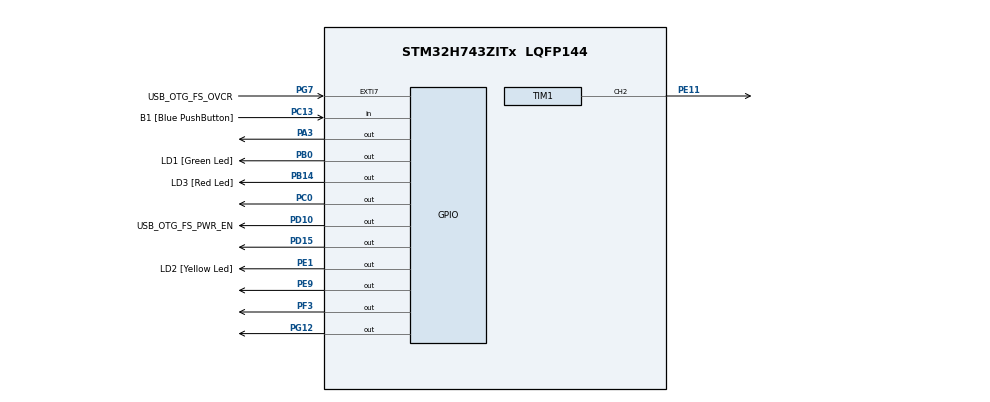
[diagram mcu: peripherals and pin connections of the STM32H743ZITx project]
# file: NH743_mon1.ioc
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Mcu.Family=STM32H7
Mcu.Name=STM32H743ZITx
Mcu.Package=LQFP144
NVIC.PriorityGroup=NVIC_PRIORITYGROUP_4
PA1.Signal=ETH_REF_CLK
PA11.Signal=USB_OTG_FS_DM
PA12.Signal=USB_OTG_FS_DP
PA13\ (JTMS/SWDIO).GPIO_Label=JTMS
PA13\ (JTMS/SWDIO).Signal=DEBUG_JTMS-SWDIO
PA14\ (JTCK/SWCLK).GPIO_Label=JTCK
PA14\ (JTCK/SWCLK).Signal=DEBUG_JTCK-SWCLK
PA2.Signal=ETH_MDIO
PA3.GPIO_Speed=GPIO_SPEED_FREQ_HIGH
PA3.PinState=GPIO_PIN_SET
PA3.Signal=GPIO_Output
PA7.Signal=ETH_CRS_DV
PA8.Signal=USB_OTG_FS_SOF
PA9.Signal=USB_OTG_FS_VBUS
PB0.GPIO_Label=LD1 [Green Led]
PB0.Signal=GPIO_Output
PB13.Signal=ETH_TXD1
PB14.GPIO_Label=LD3 [Red Led]
PB14.Signal=GPIO_Output
PC0.GPIO_Speed=GPIO_SPEED_FREQ_HIGH
PC0.PinState=GPIO_PIN_SET
PC0.Signal=GPIO_Output
PC1.Signal=ETH_MDC
PC13.GPIO_Label=B1 [Blue PushButton]
PC13.Signal=GPIO_Input
PC14-OSC32_IN\ (OSC32_IN).Signal=RCC_OSC32_IN
PC15-OSC32_OUT\ (OSC32_OUT).Signal=RCC_OSC32_OUT
PC4.Signal=ETH_RXD0
PC5.Signal=ETH_RXD1
PD10.GPIO_Label=USB_OTG_FS_PWR_EN
PD10.Signal=GPIO_Output
PD15.Signal=GPIO_Output
PD8.GPIO_Label=STLINK_RX
PD8.Signal=USART3_TX
PD9.GPIO_Label=STLINK_TX
PD9.Signal=USART3_RX
PE1.GPIO_Label=LD2 [Yellow Led]
PE1.Signal=GPIO_Output
PE11.Signal=S_TIM1_CH2
PE14.Signal=S_TIM1_CH4
PE9.Signal=GPIO_Output
PF3.GPIO_Speed=GPIO_SPEED_FREQ_HIGH
PF3.PinState=GPIO_PIN_SET
PF3.Signal=GPIO_Output
PG11.Signal=ETH_TX_EN
PG12.GPIO_Speed=GPIO_SPEED_FREQ_HIGH
PG12.PinState=GPIO_PIN_SET
PG12.Signal=GPIO_Output
PG13.Signal=ETH_TXD0
PG7.GPIO_Label=USB_OTG_FS_OVCR
PG7.Signal=GPXTI7
PH0-OSC_IN\ (PH0).Signal=RCC_OSC_IN
PH1-OSC_OUT\ (PH1).Signal=RCC_OSC_OUT
ProjectManager.HeapSize=0x200
ProjectManager.StackSize=0x400
ProjectManager.TargetToolchain=STM32CubeIDE
RCC.ADCFreq_Value=129000000
RCC.APB1Freq_Value=16000000
RCC.APB2Freq_Value=16000000
RCC.APB3Freq_Value=16000000
RCC.APB4Freq_Value=16000000
RCC.CortexFreq_Value=64000000
RCC.HCLKFreq_Value=16000000
RCC.HPRE=RCC_HCLK_DIV4
RCC.SYSCLKFreq_VALUE=64000000
RCC.USBFreq_Value=129000000
SH.S_TIM1_CH2.0=TIM1_CH2,PWM Generation2 CH2
SH.S_TIM1_CH4.0=TIM1_CH4
TIM1.AutoReloadPreload=TIM_AUTORELOAD_PRELOAD_ENABLE
TIM1.AutomaticOutput=TIM_AUTOMATICOUTPUT_DISABLE
TIM1.Break2Polarity=TIM_BREAK2POLARITY_LOW
TIM1.BreakPolarity=TIM_BREAKPOLARITY_HIGH
TIM1.Channel-PWM\ Generation2\ CH2=TIM_CHANNEL_2
TIM1.OC2Preload_PWM=DISABLE
TIM1.OCIdleState_2=TIM_OCIDLESTATE_SET
TIM1.OCMode_PWM-PWM\ Generation2\ CH2=TIM_OCMODE_PWM2
TIM1.OCPolarity_2=TIM_OCPOLARITY_LOW
TIM1.Period=30000
TIM1.Pulse-PWM\ Generation2\ CH2=7000
TIM1.RepetitionCounter=0
TIM1.TIM_MasterOutputTrigger=TIM_TRGO_ENABLE
TIM1.TIM_MasterOutputTrigger2=TIM_TRGO2_ENABLE
board=NUCLEO-H743ZI2

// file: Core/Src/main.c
/* USER CODE BEGIN Header */
/**
  ******************************************************************************
  * @file           : main.c
  * @brief          : Main program body
  ******************************************************************************
  * @attention
  *
  * Copyright (c) 2024 STMicroelectronics.
  * All rights reserved.
  *
  * This software is licensed under terms that can be found in the LICENSE file
  * in the root directory of this software component.
  * If no LICENSE file comes with this software, it is provided AS-IS.
  *
  ******************************************************************************
  Программа управления электродвигателем (мотором) постоянного тока.
  Используемое оборудование:
  1. NUCLEO-H743ZI2 (верс. NUH743ZI$AT1, MB1364C, MB1364-H743ZI-C01 F192404187)
  с  микроконтроллером STM743ZIT6U;
  2. MonsterMoto-Shield на базе VNH2SP3;
  3. Электродвигатель (мотор) постоянного тока;

  Среда разработки STM32CubeIDE v. 1.14.0
  Татаринцев Н.И, 01.05.2024 г.

  ******************************************************************************
  */
/* USER CODE END Header */
#include "main.h"

TIM_HandleTypeDef htim1;

void SystemClock_Config(void);
static void MX_GPIO_Init(void);
static void MX_TIM1_Init(void);

int main(void)
{

  /* MCU Configuration--------------------------------------------------------*/

  /* Reset of all peripherals, Initializes the Flash interface and the Systick. */
  HAL_Init();

  /* Configure the system clock */
  SystemClock_Config();

  /* Initialize all configured peripherals */
  MX_GPIO_Init();
  MX_TIM1_Init();

  /* USER CODE BEGIN 2 */

  /* ЗАПУСК ШИМ */

  /* Запуск ШИМ моста/мотора M1.
     Таймер 1, канал 2, Коннектор/Пин CN10/6, Порт PE11 (TIM1_CH2); */
     HAL_TIM_PWM_Start_IT(&htim1, TIM_CHANNEL_2);

     /* USER CODE END 2 */

  /* Infinite loop */
  /* USER CODE BEGIN WHILE */
  while (1)
  {

  /* ВРАЩЕНИЕ ЭЛЕКТРОДВИГАТЕЛЯ (МОТОРА) M1 ПРОТИВ ЧАСОВОЙ СТРЕЛКИ (CCW): */

	  /* Установка разрешения (EN1) на работу моста/мотора М1.
	     Коннектор/Пин CN9/1, Порт PA3; */
	  	 HAL_GPIO_WritePin(GPIOA, GPIO_PIN_3, GPIO_PIN_SET);

	  /* Разрешение на вращение мотора М1 против часовой стрелки (CCW).
	     Вход В драйвера 1 (INB1), Коннектор/Пин CN7/20, Порт PF3; */
	     HAL_GPIO_WritePin(GPIOF, GPIO_PIN_3, GPIO_PIN_SET);

	  /* Запрет на вращение мотора М1 по часовой стрелке (CW).
	     Вход В драйвера 1 (INA1),Коннектор/Пин CN10/2, Порт PG12; */
	  	 HAL_GPIO_WritePin(GPIOG, GPIO_PIN_12, GPIO_PIN_RESET);

	  /* Задержка времени на вращение мотора М1 против часовой стрелки */
	  	 HAL_Delay(5000);
      /* Снятие разрешения (EN1) на работу моста/мотора М1.
         Коннектор/Пин CN9/1, Порт PA3; */
	  	 HAL_GPIO_WritePin(GPIOA, GPIO_PIN_3, GPIO_PIN_RESET);
	     HAL_Delay(1000);

  /* ВРАЩЕНИЕ ЭЛЕКТРОДВИГАТЕЛЯ (МОТОРА) M1 ПО ЧАСОВОЙ СТРЕЛКЕ (CW):

       /* Установка разрешения (EN1) на работу моста/мотора М1.
          Коннектор/Пин CN9/1, Порт PA3; */
	  	  HAL_GPIO_WritePin(GPIOA, GPIO_PIN_3, GPIO_PIN_SET);

	   /* Разрешение на вращение мотора М1 по часовой стрелке (CW).
	      Вход В драйвера 1 (INA1), Коннектор/Пин CN10/2, Порт PG12; */
	  	  HAL_GPIO_WritePin(GPIOG, GPIO_PIN_12, GPIO_PIN_SET);

	   /* Запрет на вращение мотора М1 против часовой стрелки (CCW).
	  	  Вход В драйвера 1 (INB1), Коннектор/Пин CN7/20, Порт PF3; */
	   	  HAL_GPIO_WritePin(GPIOF, GPIO_PIN_3, GPIO_PIN_RESET);

	   	/* Задержка времени на вращение мотора М1 по часовой стрелке */
	   	   HAL_Delay(5000);

	   	/* Снятие разрешения (EN1) на работу моста/мотора М1.
	   	   Коннектор/Пин CN9/1, Порт PA3; */
	       HAL_GPIO_WritePin(GPIOA, GPIO_PIN_3, GPIO_PIN_RESET);
	       HAL_Delay(1000);

    /* USER CODE END WHILE */

  }
}

void SystemClock_Config(void)
{
  RCC_OscInitTypeDef RCC_OscInitStruct = {0};
  RCC_ClkInitTypeDef RCC_ClkInitStruct = {0};

  /** Supply configuration update enable
  */
  HAL_PWREx_ConfigSupply(PWR_LDO_SUPPLY);

  /** Configure the main internal regulator output voltage
  */
  __HAL_PWR_VOLTAGESCALING_CONFIG(PWR_REGULATOR_VOLTAGE_SCALE3);

  while(!__HAL_PWR_GET_FLAG(PWR_FLAG_VOSRDY)) {}

  /** Initializes the RCC Oscillators according to the specified parameters
  * in the RCC_OscInitTypeDef structure.
  */
  RCC_OscInitStruct.OscillatorType = RCC_OSCILLATORTYPE_HSI;
  RCC_OscInitStruct.HSIState = RCC_HSI_DIV1;
  RCC_OscInitStruct.HSICalibrationValue = RCC_HSICALIBRATION_DEFAULT;
  RCC_OscInitStruct.PLL.PLLState = RCC_PLL_NONE;
  if (HAL_RCC_OscConfig(&RCC_OscInitStruct) != HAL_OK)
  {
    Error_Handler();
  }

  /** Initializes the CPU, AHB and APB buses clocks
  */
  RCC_ClkInitStruct.ClockType = RCC_CLOCKTYPE_HCLK|RCC_CLOCKTYPE_SYSCLK
                              |RCC_CLOCKTYPE_PCLK1|RCC_CLOCKTYPE_PCLK2
                              |RCC_CLOCKTYPE_D3PCLK1|RCC_CLOCKTYPE_D1PCLK1;
  RCC_ClkInitStruct.SYSCLKSource = RCC_SYSCLKSOURCE_HSI;
  RCC_ClkInitStruct.SYSCLKDivider = RCC_SYSCLK_DIV1;
  RCC_ClkInitStruct.AHBCLKDivider = RCC_HCLK_DIV4;
  RCC_ClkInitStruct.APB3CLKDivider = RCC_APB3_DIV1;
  RCC_ClkInitStruct.APB1CLKDivider = RCC_APB1_DIV1;
  RCC_ClkInitStruct.APB2CLKDivider = RCC_APB2_DIV1;
  RCC_ClkInitStruct.APB4CLKDivider = RCC_APB4_DIV1;

  if (HAL_RCC_ClockConfig(&RCC_ClkInitStruct, FLASH_LATENCY_0) != HAL_OK)
  {
    Error_Handler();
  }
}

static void MX_TIM1_Init(void)
{

  TIM_MasterConfigTypeDef sMasterConfig = {0};
  TIM_OC_InitTypeDef sConfigOC = {0};
  TIM_BreakDeadTimeConfigTypeDef sBreakDeadTimeConfig = {0};

  htim1.Instance = TIM1;
  htim1.Init.Prescaler = 0;
  htim1.Init.CounterMode = TIM_COUNTERMODE_UP;
  htim1.Init.Period = 30000;
  htim1.Init.ClockDivision = TIM_CLOCKDIVISION_DIV1;
  htim1.Init.RepetitionCounter = 0;
  htim1.Init.AutoReloadPreload = TIM_AUTORELOAD_PRELOAD_ENABLE;
  if (HAL_TIM_PWM_Init(&htim1) != HAL_OK)
  {
    Error_Handler();
  }
  sMasterConfig.MasterOutputTrigger = TIM_TRGO_ENABLE;
  sMasterConfig.MasterOutputTrigger2 = TIM_TRGO2_ENABLE;
  sMasterConfig.MasterSlaveMode = TIM_MASTERSLAVEMODE_DISABLE;
  if (HAL_TIMEx_MasterConfigSynchronization(&htim1, &sMasterConfig) != HAL_OK)
  {
    Error_Handler();
  }
  sConfigOC.OCMode = TIM_OCMODE_PWM2;
  sConfigOC.Pulse = 7000;
  sConfigOC.OCPolarity = TIM_OCPOLARITY_LOW;
  sConfigOC.OCNPolarity = TIM_OCNPOLARITY_HIGH;
  sConfigOC.OCFastMode = TIM_OCFAST_DISABLE;
  sConfigOC.OCIdleState = TIM_OCIDLESTATE_SET;
  sConfigOC.OCNIdleState = TIM_OCNIDLESTATE_RESET;
  if (HAL_TIM_PWM_ConfigChannel(&htim1, &sConfigOC, TIM_CHANNEL_2) != HAL_OK)
  {
    Error_Handler();
  }
  __HAL_TIM_DISABLE_OCxPRELOAD(&htim1, TIM_CHANNEL_2);
  sBreakDeadTimeConfig.OffStateRunMode = TIM_OSSR_DISABLE;
  sBreakDeadTimeConfig.OffStateIDLEMode = TIM_OSSI_DISABLE;
  sBreakDeadTimeConfig.LockLevel = TIM_LOCKLEVEL_OFF;
  sBreakDeadTimeConfig.DeadTime = 0;
  sBreakDeadTimeConfig.BreakState = TIM_BREAK_DISABLE;
  sBreakDeadTimeConfig.BreakPolarity = TIM_BREAKPOLARITY_HIGH;
  sBreakDeadTimeConfig.BreakFilter = 0;
  sBreakDeadTimeConfig.Break2State = TIM_BREAK2_DISABLE;
  sBreakDeadTimeConfig.Break2Polarity = TIM_BREAK2POLARITY_LOW;
  sBreakDeadTimeConfig.Break2Filter = 0;
  sBreakDeadTimeConfig.AutomaticOutput = TIM_AUTOMATICOUTPUT_DISABLE;
  if (HAL_TIMEx_ConfigBreakDeadTime(&htim1, &sBreakDeadTimeConfig) != HAL_OK)
  {
    Error_Handler();
  }
  HAL_TIM_MspPostInit(&htim1);

}

static void MX_GPIO_Init(void)
{
  GPIO_InitTypeDef GPIO_InitStruct = {0};

  /* GPIO Ports Clock Enable */
  __HAL_RCC_GPIOC_CLK_ENABLE();
  __HAL_RCC_GPIOF_CLK_ENABLE();
  __HAL_RCC_GPIOH_CLK_ENABLE();
  __HAL_RCC_GPIOA_CLK_ENABLE();
  __HAL_RCC_GPIOB_CLK_ENABLE();
  __HAL_RCC_GPIOE_CLK_ENABLE();
  __HAL_RCC_GPIOD_CLK_ENABLE();
  __HAL_RCC_GPIOG_CLK_ENABLE();

  /*Configure GPIO pin Output Level */
  HAL_GPIO_WritePin(GPIOF, GPIO_PIN_3, GPIO_PIN_SET);

  /*Configure GPIO pin Output Level */
  HAL_GPIO_WritePin(GPIOC, GPIO_PIN_0, GPIO_PIN_SET);

  /*Configure GPIO pin Output Level */
  HAL_GPIO_WritePin(GPIOA, GPIO_PIN_3, GPIO_PIN_SET);

  /*Configure GPIO pin Output Level */
  HAL_GPIO_WritePin(GPIOB, LD1_Pin|LD3_Pin, GPIO_PIN_RESET);

  /*Configure GPIO pin Output Level */
  HAL_GPIO_WritePin(GPIOE, GPIO_PIN_9|LD2_Pin, GPIO_PIN_RESET);

  /*Configure GPIO pin Output Level */
  HAL_GPIO_WritePin(GPIOD, USB_OTG_FS_PWR_EN_Pin|GPIO_PIN_15, GPIO_PIN_RESET);

  /*Configure GPIO pin Output Level */
  HAL_GPIO_WritePin(GPIOG, GPIO_PIN_12, GPIO_PIN_SET);

  /*Configure GPIO pin : B1_Pin */
  GPIO_InitStruct.Pin = B1_Pin;
  GPIO_InitStruct.Mode = GPIO_MODE_INPUT;
  GPIO_InitStruct.Pull = GPIO_NOPULL;
  HAL_GPIO_Init(B1_GPIO_Port, &GPIO_InitStruct);

  /*Configure GPIO pin : PF3 */
  GPIO_InitStruct.Pin = GPIO_PIN_3;
  GPIO_InitStruct.Mode = GPIO_MODE_OUTPUT_PP;
  GPIO_InitStruct.Pull = GPIO_NOPULL;
  GPIO_InitStruct.Speed = GPIO_SPEED_FREQ_HIGH;
  HAL_GPIO_Init(GPIOF, &GPIO_InitStruct);

  /*Configure GPIO pin : PC0 */
  GPIO_InitStruct.Pin = GPIO_PIN_0;
  GPIO_InitStruct.Mode = GPIO_MODE_OUTPUT_PP;
  GPIO_InitStruct.Pull = GPIO_NOPULL;
  GPIO_InitStruct.Speed = GPIO_SPEED_FREQ_HIGH;
  HAL_GPIO_Init(GPIOC, &GPIO_InitStruct);

  /*Configure GPIO pins : PC1 PC4 PC5 */
  GPIO_InitStruct.Pin = GPIO_PIN_1|GPIO_PIN_4|GPIO_PIN_5;
  GPIO_InitStruct.Mode = GPIO_MODE_AF_PP;
  GPIO_InitStruct.Pull = GPIO_NOPULL;
  GPIO_InitStruct.Speed = GPIO_SPEED_FREQ_LOW;
  GPIO_InitStruct.Alternate = GPIO_AF11_ETH;
  HAL_GPIO_Init(GPIOC, &GPIO_InitStruct);

  /*Configure GPIO pins : PA1 PA2 PA7 */
  GPIO_InitStruct.Pin = GPIO_PIN_1|GPIO_PIN_2|GPIO_PIN_7;
  GPIO_InitStruct.Mode = GPIO_MODE_AF_PP;
  GPIO_InitStruct.Pull = GPIO_NOPULL;
  GPIO_InitStruct.Speed = GPIO_SPEED_FREQ_LOW;
  GPIO_InitStruct.Alternate = GPIO_AF11_ETH;
  HAL_GPIO_Init(GPIOA, &GPIO_InitStruct);

  /*Configure GPIO pin : PA3 */
  GPIO_InitStruct.Pin = GPIO_PIN_3;
  GPIO_InitStruct.Mode = GPIO_MODE_OUTPUT_PP;
  GPIO_InitStruct.Pull = GPIO_NOPULL;
  GPIO_InitStruct.Speed = GPIO_SPEED_FREQ_HIGH;
  HAL_GPIO_Init(GPIOA, &GPIO_InitStruct);

  /*Configure GPIO pins : LD1_Pin LD3_Pin */
  GPIO_InitStruct.Pin = LD1_Pin|LD3_Pin;
  GPIO_InitStruct.Mode = GPIO_MODE_OUTPUT_PP;
  GPIO_InitStruct.Pull = GPIO_NOPULL;
  GPIO_InitStruct.Speed = GPIO_SPEED_FREQ_LOW;
  HAL_GPIO_Init(GPIOB, &GPIO_InitStruct);

  /*Configure GPIO pins : PE9 LD2_Pin */
  GPIO_InitStruct.Pin = GPIO_PIN_9|LD2_Pin;
  GPIO_InitStruct.Mode = GPIO_MODE_OUTPUT_PP;
  GPIO_InitStruct.Pull = GPIO_NOPULL;
  GPIO_InitStruct.Speed = GPIO_SPEED_FREQ_LOW;
  HAL_GPIO_Init(GPIOE, &GPIO_InitStruct);

  /*Configure GPIO pin : PB13 */
  GPIO_InitStruct.Pin = GPIO_PIN_13;
  GPIO_InitStruct.Mode = GPIO_MODE_AF_PP;
  GPIO_InitStruct.Pull = GPIO_NOPULL;
  GPIO_InitStruct.Speed = GPIO_SPEED_FREQ_LOW;
  GPIO_InitStruct.Alternate = GPIO_AF11_ETH;
  HAL_GPIO_Init(GPIOB, &GPIO_InitStruct);

  /*Configure GPIO pins : STLINK_RX_Pin STLINK_TX_Pin */
  GPIO_InitStruct.Pin = STLINK_RX_Pin|STLINK_TX_Pin;
  GPIO_InitStruct.Mode = GPIO_MODE_AF_PP;
  GPIO_InitStruct.Pull = GPIO_NOPULL;
  GPIO_InitStruct.Speed = GPIO_SPEED_FREQ_LOW;
  GPIO_InitStruct.Alternate = GPIO_AF7_USART3;
  HAL_GPIO_Init(GPIOD, &GPIO_InitStruct);

  /*Configure GPIO pins : USB_OTG_FS_PWR_EN_Pin PD15 */
  GPIO_InitStruct.Pin = USB_OTG_FS_PWR_EN_Pin|GPIO_PIN_15;
  GPIO_InitStruct.Mode = GPIO_MODE_OUTPUT_PP;
  GPIO_InitStruct.Pull = GPIO_NOPULL;
  GPIO_InitStruct.Speed = GPIO_SPEED_FREQ_LOW;
  HAL_GPIO_Init(GPIOD, &GPIO_InitStruct);

  /*Configure GPIO pin : USB_OTG_FS_OVCR_Pin */
  GPIO_InitStruct.Pin = USB_OTG_FS_OVCR_Pin;
  GPIO_InitStruct.Mode = GPIO_MODE_IT_RISING;
  GPIO_InitStruct.Pull = GPIO_NOPULL;
  HAL_GPIO_Init(USB_OTG_FS_OVCR_GPIO_Port, &GPIO_InitStruct);

  /*Configure GPIO pins : PA8 PA11 PA12 */
  GPIO_InitStruct.Pin = GPIO_PIN_8|GPIO_PIN_11|GPIO_PIN_12;
  GPIO_InitStruct.Mode = GPIO_MODE_AF_PP;
  GPIO_InitStruct.Pull = GPIO_NOPULL;
  GPIO_InitStruct.Speed = GPIO_SPEED_FREQ_LOW;
  GPIO_InitStruct.Alternate = GPIO_AF10_OTG1_FS;
  HAL_GPIO_Init(GPIOA, &GPIO_InitStruct);

  /*Configure GPIO pins : PG11 PG13 */
  GPIO_InitStruct.Pin = GPIO_PIN_11|GPIO_PIN_13;
  GPIO_InitStruct.Mode = GPIO_MODE_AF_PP;
  GPIO_InitStruct.Pull = GPIO_NOPULL;
  GPIO_InitStruct.Speed = GPIO_SPEED_FREQ_LOW;
  GPIO_InitStruct.Alternate = GPIO_AF11_ETH;
  HAL_GPIO_Init(GPIOG, &GPIO_InitStruct);

  /*Configure GPIO pin : PG12 */
  GPIO_InitStruct.Pin = GPIO_PIN_12;
  GPIO_InitStruct.Mode = GPIO_MODE_OUTPUT_PP;
  GPIO_InitStruct.Pull = GPIO_NOPULL;
  GPIO_InitStruct.Speed = GPIO_SPEED_FREQ_HIGH;
  HAL_GPIO_Init(GPIOG, &GPIO_InitStruct);

}

void Error_Handler(void)
{
  __disable_irq();
  while (1)
  {
  }
}
